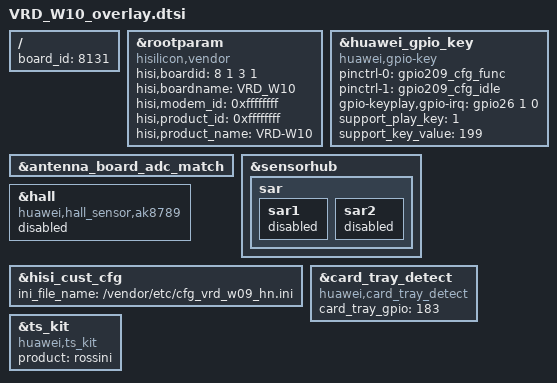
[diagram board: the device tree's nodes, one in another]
/**
 * Copyright (C) 2014 Hisilicon Ltd.
 *
 *  This program is free software; you can redistribute it and/or modify
 *  it under the terms of the GNU General Public License version 2 as
 *  publishhed by the Free Software Foundation.
 */

/include/ "VRD_W09_VA_overlay.dtsi"

/ {
    board_id = <8131>;
};

	&rootparam {
		compatible = "hisilicon,vendor";
		hisi,boardid = <8 1 3 1>;
		hisi,boardname = "VRD_W10";
		hisi,modem_id = <0xffffffff>;
		hisi,product_id = <0xffffffff>;
		hisi,product_name = "VRD-W10";
	};
	&huawei_gpio_key{
		compatible = "huawei,gpio-key";
		pinctrl-names = "default", "idle";
		pinctrl-0 = <&gpio209_cfg_func>;
		pinctrl-1 = <&gpio209_cfg_idle>;
		gpio-keyplay,gpio-irq = <&gpio26 1 0>;
		support_play_key = <1>;
		support_key_value = <199>;
		status = "ok";
	};
	&antenna_board_adc_match{
		status = "ok";
	};
	&sensorhub{
		sar{
			sar1{
				status = "disabled";
			};
			sar2{
				status = "disabled";
			};
		};
	};
	&hall {
		compatible = "huawei,hall_sensor,ak8789";
		status = "disabled";
	};
	/*hisi customize*/
	&hisi_cust_cfg {
		ini_file_name = "/vendor/etc/cfg_vrd_w09_hn.ini";
	};
	&card_tray_detect{
		compatible = "huawei,card_tray_detect";
		card_tray_gpio = <183>;
	};
	/*ts kit*/
	&ts_kit {
		compatible = "huawei,ts_kit";
		product = "rossini";
	};
